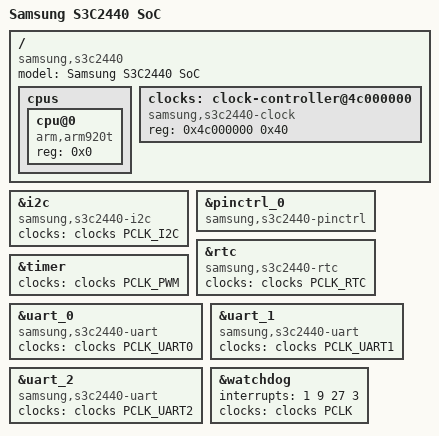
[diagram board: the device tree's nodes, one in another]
// SPDX-License-Identifier: GPL-2.0
/*
 * Samsung's S3C2416 SoC device tree source
 *
 * Copyright (c) 2013 Heiko Stuebner <heiko@sntech.de>
 */

#include <dt-bindings/clock/s3c2410.h>
#include "s3c24xx.dtsi"
#include "s3c2416-pinctrl.dtsi"

/ {
	model = "Samsung S3C2440 SoC";
	compatible = "samsung,s3c2440";

	cpus {
		#address-cells = <1>;
		#size-cells = <0>;

		cpu@0 {
			device_type = "cpu";
			compatible = "arm,arm920t";
			reg = <0x0>;
		};
	};

	clocks: clock-controller@4c000000 {
		compatible = "samsung,s3c2440-clock";
		reg = <0x4c000000 0x40>;
		#clock-cells = <1>;
	};
};

&i2c {
	compatible = "samsung,s3c2440-i2c";
	clocks = <&clocks PCLK_I2C>;
	clock-names = "i2c";
};

&pinctrl_0 {
	compatible = "samsung,s3c2440-pinctrl";
};

&rtc {
	compatible = "samsung,s3c2440-rtc";
	clocks = <&clocks PCLK_RTC>;
	clock-names = "rtc";
};

&timer {
	clocks = <&clocks PCLK_PWM>;
	clock-names = "timers";
};

&uart_0 {
	compatible = "samsung,s3c2440-uart";
	clock-names = "uart", "clk_uart_baud2",
			"clk_uart_baud3";
	clocks = <&clocks PCLK_UART0>;
};

&uart_1 {
	compatible = "samsung,s3c2440-uart";
	clock-names = "uart", "clk_uart_baud2",
			"clk_uart_baud3";
	clocks = <&clocks PCLK_UART1>;
};

&uart_2 {
	compatible = "samsung,s3c2440-uart";
	clock-names = "uart", "clk_uart_baud2",
			"clk_uart_baud3";
	clocks = <&clocks PCLK_UART2>;
};

&watchdog {
	interrupts = <1 9 27 3>;
	clocks = <&clocks PCLK>;
	clock-names = "watchdog";
};
